# CY8C5868AXI_LP035 register map
File version: 0.1
Registers are 8-bit, read-write, no defined reset value unless marked. A register's access mark holds for its fields unless they carry their own. Offsets are from the block's base; [hi:lo] are bit positions; 'fields as' and 'values as' point back to an identical list.

## Control_Reg_Direction
Base 0x00000000
0x40006579 Control_Reg_Direction_CONTROL_REG

## PWM_Front_Right
Base 0x00000000
0x40006528 PWM_Front_Right_COMPARE_Reg 16-bit — UDB.D0 - Assigned Compare Value
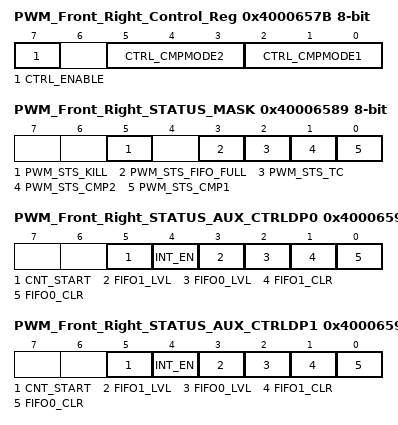
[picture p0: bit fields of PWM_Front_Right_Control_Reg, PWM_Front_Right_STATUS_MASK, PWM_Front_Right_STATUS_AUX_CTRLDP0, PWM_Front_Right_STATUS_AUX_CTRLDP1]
0x4000657B PWM_Front_Right_Control_Reg — UDB Control Register - Assigned Control Register Value
  [7] CTRL_ENABLE — Enable the PWM
  [5:3] CTRL_CMPMODE2 — Compare mode 2
  [2:0] CTRL_CMPMODE1 — Compare mode 1
0x40006589 PWM_Front_Right_STATUS_MASK — UDB Status bits Interrupt Mask Enable Register
  [5] PWM_STS_KILL ro — Enables the Interrupt on Kill
  [3] PWM_STS_FIFO_FULL ro — FIFO Full Status Mask
  [2] PWM_STS_TC ro — Enables the Interrupt on Terminal Count
  [1] PWM_STS_CMP2 ro — Enables the Interrupt on Compare 2
  [0] PWM_STS_CMP1 ro — Enables the Interrupt on Compare 1
0x40006598 PWM_Front_Right_STATUS_AUX_CTRLDP0 — UDB Auxilliary Control Register
  [5] CNT_START — FIFO0 clear
    0=E_CNT_START0 (Disable counter); 1=E_CNT_START1 (Enable counter)
  [4] INT_EN
    0=E_INT_EN0 (Interrupt disabled); 1=E_INT_EN1 (Interrupt enabled)
  [3] FIFO1_LVL — FIFO level
    0=E_FIFO_LVL_0 (FIFO LVL: input mode: FIFO not full; output mode: FIFO not empty); 1=E_FIFO_LVL_1 (FIFO LVL: input mode: FIFO at least 1/2 empty; output mode: FIFO at least 1/2 full)
  [2] FIFO0_LVL — FIFO level
    values as FIFO1_LVL
  [1] FIFO1_CLR — FIFO1 clear
    0=E_FIFO_CLR_0 (Normal FIFO operation); 1=E_FIFO_CLR_1 (Clear FIFO state)
  [0] FIFO0_CLR — FIFO0 clear
    values as FIFO1_CLR
0x40006599 PWM_Front_Right_STATUS_AUX_CTRLDP1 — UDB Auxilliary Control Register
  fields as PWM_Front_Right_STATUS_AUX_CTRLDP0

## PWM_Front_Left
Base 0x00000000
0x4000652A PWM_Front_Left_COMPARE_Reg 16-bit — UDB.D0 - Assigned Compare Value
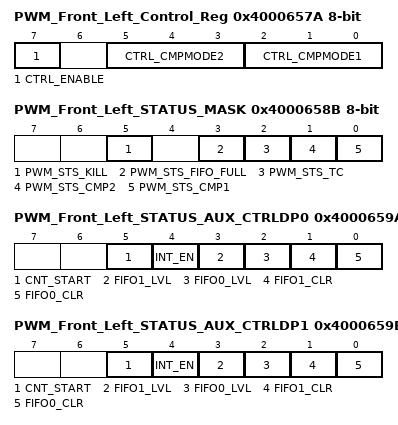
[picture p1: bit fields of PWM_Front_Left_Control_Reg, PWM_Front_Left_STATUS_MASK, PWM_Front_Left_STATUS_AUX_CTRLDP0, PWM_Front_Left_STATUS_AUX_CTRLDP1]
0x4000657A PWM_Front_Left_Control_Reg — UDB Control Register - Assigned Control Register Value
  [7] CTRL_ENABLE — Enable the PWM
  [5:3] CTRL_CMPMODE2 — Compare mode 2
  [2:0] CTRL_CMPMODE1 — Compare mode 1
0x4000658B PWM_Front_Left_STATUS_MASK — UDB Status bits Interrupt Mask Enable Register
  [5] PWM_STS_KILL ro — Enables the Interrupt on Kill
  [3] PWM_STS_FIFO_FULL ro — FIFO Full Status Mask
  [2] PWM_STS_TC ro — Enables the Interrupt on Terminal Count
  [1] PWM_STS_CMP2 ro — Enables the Interrupt on Compare 2
  [0] PWM_STS_CMP1 ro — Enables the Interrupt on Compare 1
0x4000659A PWM_Front_Left_STATUS_AUX_CTRLDP0 — UDB Auxilliary Control Register
  [5] CNT_START — FIFO0 clear
    0=E_CNT_START0 (Disable counter); 1=E_CNT_START1 (Enable counter)
  [4] INT_EN
    0=E_INT_EN0 (Interrupt disabled); 1=E_INT_EN1 (Interrupt enabled)
  [3] FIFO1_LVL — FIFO level
    0=E_FIFO_LVL_0 (FIFO LVL: input mode: FIFO not full; output mode: FIFO not empty); 1=E_FIFO_LVL_1 (FIFO LVL: input mode: FIFO at least 1/2 empty; output mode: FIFO at least 1/2 full)
  [2] FIFO0_LVL — FIFO level
    values as FIFO1_LVL
  [1] FIFO1_CLR — FIFO1 clear
    0=E_FIFO_CLR_0 (Normal FIFO operation); 1=E_FIFO_CLR_1 (Clear FIFO state)
  [0] FIFO0_CLR — FIFO0 clear
    values as FIFO1_CLR
0x4000659B PWM_Front_Left_STATUS_AUX_CTRLDP1 — UDB Auxilliary Control Register
  fields as PWM_Front_Left_STATUS_AUX_CTRLDP0

## PWM_Back_Left
Base 0x00000000
0x400043A3 PWM_Back_Left_GLOBAL_ENABLE — PM.ACT.CFG
  [3:0] en_timer — Enable timer/counters.
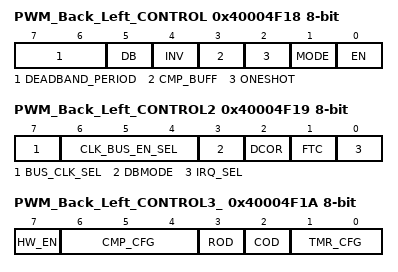
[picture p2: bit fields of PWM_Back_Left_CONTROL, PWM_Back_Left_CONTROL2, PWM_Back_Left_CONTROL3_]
0x40004F18 PWM_Back_Left_CONTROL — TMRx.CFG0
  [7:6] DEADBAND_PERIOD
  [5] DB — Deadband mode--Deadband phases phi1 and phi2 are outputted on CMP and TC output pins respectively.
    0=Timer (CMP and TC are output.); 1=Deadband (PHI1 (instead of CMP) and PHI2 (instead of TC) are output.)
  [4] INV — Invert sense of TIMEREN signal
  [3] CMP_BUFF — Buffer compare register. Compare register updates only on timer terminal count.
  [2] ONESHOT — Timer stops upon reaching stop condition defined by TMR_CFG bits. Can be restarted by asserting TIMER RESET or disabling and re-enabling block.
  [1] MODE ro — Mode. (0 = Timer; 1 = Comparator)
    0=Timer mode. CNT/CMP register holds timer count value.; 1=Comparator mode. CNT/CMP register holds comparator threshold value.
  [0] EN — Enables timer/comparator.
0x40004F19 PWM_Back_Left_CONTROL2 — TMRx.CFG1
  [7] BUS_CLK_SEL — Bus Clock selection.
  [6:4] CLK_BUS_EN_SEL — Digital Global Clock selection.
  [3] DBMODE — Deadband mode (asynchronous/synchronous). CMP output pin is also affected when not in deadband mode (CFG0.DEADBAND).
  [2] DCOR — Disable Clear on Read (DCOR) of Status Register SR0.
  [1] FTC — First Terminal Count (FTC). Setting this bit forces a single pulse on the TC pin when first enabled.
    0=Disable FTC (Disable the single cycle pulse, which signifies the timer is starting.); 1=Enable FTC (Enable the single cycle pulse, which signifies the timer is starting.)
  [0] IRQ_SEL — Irq selection. (0 = raw interrupts; 1 = status register interrupts)
0x40004F1A PWM_Back_Left_CONTROL3_ — TMRx.CFG2
  [7] HW_EN — When set Timer Enable controls counting.
  [6:4] CMP_CFG — Comparator configurations
    0=Equal (Compare Equal); 1=Less than (Compare Less Than); 2=Less than or equal (Compare Less Than or Equal .); 3=Greater (Compare Greater Than .); 4=Greater than or equal (Compare Greater Than or Equal)
  [3] ROD — Reset On Disable (ROD). Resets internal state of output logic
  [2] COD — Clear On Disable (COD). Clears or gates outputs to zero.
  [1:0] TMR_CFG — Timer configuration (MODE = 0): 000 = Continuous; 001 = Pulsewidth; 010 = Period; 011 = Stop on IRQ
    0=Continuous (Timer runs while EN bit of CFG0 register is set to '1'.); 1=Pulsewidth (Timer runs from positive to negative edge of TIMEREN.); 2=Period (Timer runs from positive to positive edge of TIMEREN.); 3=Irq (Timer runs until IRQ.)
0x40004F1C PWM_Back_Left_PERIOD 16-bit — TMRx.PER0 - Assigned Period
0x40004F1E PWM_Back_Left_COMPARE 16-bit — TMRx.CNT_CMP0 - Assigned Compare Value

## I2C
Base 0x00000000
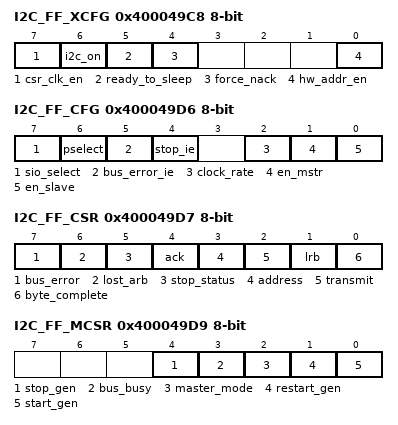
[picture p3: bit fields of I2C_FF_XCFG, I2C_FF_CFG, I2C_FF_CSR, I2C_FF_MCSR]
0x400049C8 I2C_FF_XCFG — Extended Configuration Register: I2C_XCFG
  [7] csr_clk_en, [6] i2c_on, [5] ready_to_sleep ro, [4] force_nack, [0] hw_addr_en
0x400049CA I2C_FF_ADDR — Slave Adddress Register: I2C_ADR
  [6:0] slave_address — This register holds the slave's 7-bit address.
0x400049D6 I2C_FF_CFG — Configuration Register: I2C_CFG
  [7] sio_select, [6] pselect, [5] bus_error_ie, [4] stop_ie, [2] clock_rate, [1] en_mstr, [0] en_slave
0x400049D7 I2C_FF_CSR — Control and Status Register: I2C_CSR
  [7] bus_error, [6] lost_arb, [5] stop_status, [4] ack, [3] address, [2] transmit, [1] lrb, [0] byte_complete
0x400049D8 I2C_FF_DATA — Data Register: I2C_D
  [7:0] data — This register provides read/write access to the Shift register.
0x400049D9 I2C_FF_MCSR — Master Control and Status Register: I2C_MCSR
  [4] stop_gen, [3] bus_busy ro, [2] master_mode ro, [1] restart_gen, [0] start_gen
0x400049DB I2C_FF__CLK_DIV1 — Divider of BUS_CLK low part: I2C_CLK_DIV1
  [7:0] Div
0x400049DC I2C_FF__CLK_DIV2 — Divider high part: I2C_CLK_DIV1
  [1:0] Div
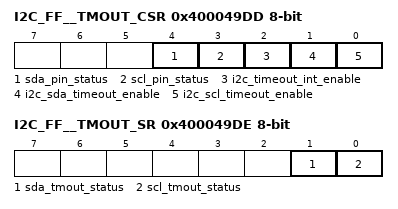
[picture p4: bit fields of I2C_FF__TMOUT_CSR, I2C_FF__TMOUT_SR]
0x400049DD I2C_FF__TMOUT_CSR — Extended Configuration Register: I2C_TMOUT_CSR
  [4] sda_pin_status, [3] scl_pin_status, [2] i2c_timeout_int_enable ro, [1] i2c_sda_timeout_enable, [0] i2c_scl_timeout_enable
0x400049DE I2C_FF__TMOUT_SR — Extended Configuration Register: I2C_TMOUT_SR
  [1] sda_tmout_status, [0] scl_tmout_status
0x400049DF I2C_FF__TMOUT_CFG0 — Extended Configuration Register: TMOUT_CFG0
  [7:0] timeout_period_lowbyte
0x400049E0 I2C_FF__TMOUT_CFG1 — Extended Configuration Register: TMOUT_CFG1
  [3:0] timeout_period_highnibble
